# HSM_HSM_AES_CE006000h register map
Vendor: Texas Instruments
Peripheral module from a debugger description file (folder AM261x).
Registers are 32-bit, read-write, reset 0x0 unless marked. A register's access mark holds for its fields unless they carry their own. Offsets are as the file gives them; lines under a group give offsets from that group; [hi:lo] are bit positions; {n}, {i} and the like mark numbered series; 'fields as' and 'values as' point back to an identical list; <NAME> marks a mode.

## HSM_AES
0x00 HSM_AES_S_KEY2_6 — XTS second key / CBC-MAC third key (Read-returns0s).
  [31:0] KEY — key data
0x04 HSM_AES_S_KEY2_7 — XTS second key (MSW for 256-bit key) / CBC-MAC third key (MSW) (Read-returns0s).
  [31:0] KEY — key data
0x08 HSM_AES_S_KEY2_4 — XTS / CCM second key / CBC-MAC third key (LSW) (Read-returns0s).
  [31:0] KEY — key data
0x0C HSM_AES_S_KEY2_5 — XTS second key (MSW for 192-bit key) / CBC-MAC third key (Read-returns0s).
  [31:0] KEY — key data
0x10 HSM_AES_S_KEY2_2 — XTS / CCM / CBC-MAC second key / Hash Key input (Read-returns0s).
  [31:0] KEY — key data
0x14 HSM_AES_S_KEY2_3 — XTS second key (MSW for 128-bit key) + CCM/CBC-MAC second key (MSW) / Hash Key input (MSW) (Read-returns0s).
  [31:0] KEY — key data
0x18 HSM_AES_S_KEY2_0 — XTS / CCM / CBC-MAC second key (LSW) / Hash Key input (LSW) (Read-returns0s).
  [31:0] KEY — key data
0x1C HSM_AES_S_KEY2_1 — XTS / CCM / CBC-MAC second key / Hash Key input (Read-returns0s).
  [31:0] KEY — key data
0x20 HSM_AES_S_KEY1_6 — Key (LSW for 256-bit key) (Read-returns0s).
  [31:0] KEY — key data
0x24 HSM_AES_S_KEY1_7 — Key (MSW for 256-bit key) (Read-returns0s).
  [31:0] KEY — key data
0x28 HSM_AES_S_KEY1_4 — Key (LSW for 192-bit key) (Read-returns0s).
  [31:0] KEY — key data
0x2C HSM_AES_S_KEY1_5 — Key (MSW for 192-bit key) (Read-returns0s).
  [31:0] KEY — key data
0x30 HSM_AES_S_KEY1_2 — Key (Read-returns0s).
  [31:0] KEY — key data
0x34 HSM_AES_S_KEY1_3 — Key (MSW for 128-bit key) (Read-returns0s).
  [31:0] KEY — key data
0x38 HSM_AES_S_KEY1_0 — Key (LSW for 128-bit key) (Read-returns0s).
  [31:0] KEY — key data
0x3C HSM_AES_S_KEY1_1 — Key (Read-returns0s).
  [31:0] KEY — key data
0x40 HSM_AES_S_IV_IN_0 — Initialization Vector input (LSW).
  [31:0] DATA — IV data
0x44 HSM_AES_S_IV_IN_1 — Initialization vector input.
  [31:0] DATA — IV data
0x48 HSM_AES_S_IV_IN_2 — Initialization vector input .
  [31:0] DATA — IV data
0x4C HSM_AES_S_IV_IN_3 — Initialization Vector input (MSW)
  [31:0] DATA — IV data
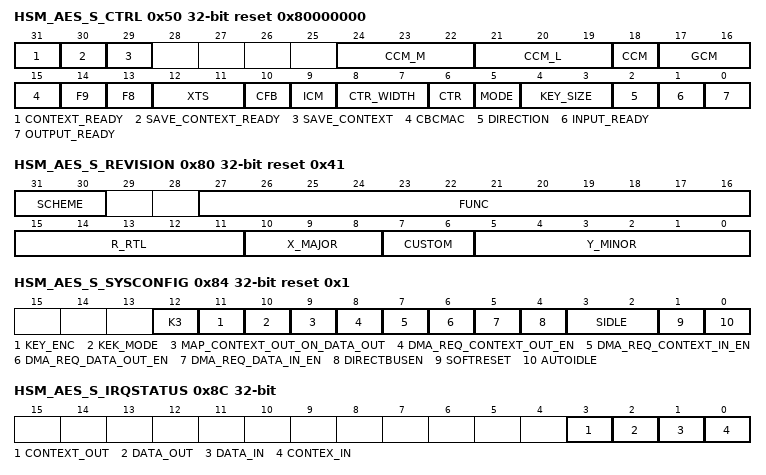
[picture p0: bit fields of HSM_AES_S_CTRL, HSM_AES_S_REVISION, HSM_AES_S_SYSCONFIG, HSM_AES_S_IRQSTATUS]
0x50 HSM_AES_S_CTRL access per field reset 0x80000000 — Register determines the mode of operation of the AES Engine.
  [31] CONTEXT_READY ro — If'1' this read-only status bit indicates that the context data registers can be overwritten and the host is permitted to write the next context.
  [30] SAVE_CONTEXT_READY ro — If'1' this read-only status bit indicates that an AES authentication TAG and/or IV block[s] is/are available for the host to retrieve. This bit is only asserted if the'save_context' bit is set to'1'. The bit is mutual exclusive with the'context_ready' bit.
  [29] SAVE_CONTEXT rw — This bit is used to indicate that an authentication TAG or result IV needs to be stored as a result context. If this bit is set context output DMA and/or interrupt will be asserted if the operation is finished and related signals are enabled.
  [24:22] CCM_M rw — Defines 'M' that indicated the length of the authentication field for CCM operations; the authentication field length equals two times [the value of CCM-M plus one]. Note that the AES Engine always returns a 128-bit authentication field of which the M least significant bytes are valid. All values are supported.
  [21:19] CCM_L rw — Defines 'L' that indicated the width of the length field for CCM operations; the length field in bytes equals the value of CMM-L plus one. Supported values for L are [programmed value]: 2 [1] 4 [3] and 8 [7].
  [18] CCM rw — AES-CCM is selected this is a combined mode using AES for both authentication and encryption. No additional mode selection is required. 0 Other mode selected 1 ccm mode selected
  [17:16] GCM rw — AES-GCM mode is selected.this is a combined mode using the Galois field multiplier GF[2^128] for authentication and AES-CTR mode for encryption the bits specify the GCM mode. 0x0 No operation 0x1 GHASH with H loaded and Y0-encrypted forced to zero 0x2 GHASH with H loaded and Y0-encrypted calculated internally 0x3 Autonomous GHASH [both H and Y0-encrypted calculated internally]
  [15] CBCMAC rw — AES-CBC MAC is selected the Direction bit must be set to'1' for this mode. 0 Other mode selected 1 cbcmac mode selected
  [14] F9 rw — AES f9 mode is selected the AES key size must be set to 128-bit for this mode. 0 Other mode selected 1 f9 selected
  [13] F8 rw — AES f8 mode is selected the AES key size must be set to 128-bit for this mode. 0 Other mode selected 1 f8 selected
  [12:11] XTS rw — AES-XTS operation is selected; the bits specify the XTS mode.01 = Previous/intermediate tweak value and'j' loaded [value is loaded via IV j is loaded via the AAD length register] 0x0 No operation 0x1 Previous/intermediate tweak value and'j' loaded [value is loaded via IV j is loaded via the AAD length register] 0x2 Key2 i and j loaded [i is loaded via IV j is loaded via the AAD length register] 0x3 Key2 and i loaded j=0 [i is loaded via IV]
  [10] CFB rw — full block AES cipher feedback mode [CFB128] is selected. 0 other mode selected 1 cfb selected
  [9] ICM rw — AES integer counter mode [ICM] is selected this is a counter mode with a 16-bit wide counter. 0 Other mode selected. 1 ICM mode selected
  [8:7] CTR_WIDTH rw — Specifies the counter width for AES-CTR mode 0x0 Counter is 32 bits 0x1 Counter is 64 bits 0x2 Counter is 128 bits 0x3 Counter is 192 bits
  [6] CTR rw — Tthis bit must also be set for GCM and CCM when encryption/decryption is required. 0 Other mode selected 1 Counter mode
  [5] MODE rw — Ecb/cbc mode 0 ecb mode 1 cbc mode
  [4:3] KEY_SIZE rw — key size 0x0 reserved 0x1 Key is 128 bits. 0x2 Key is 192 bits 0x3 Key is 256
  [2] DIRECTION rw — If set to'1' an encrypt operation is performed. If set to'0' a decrypt operation is performed. Read0 decryption is selected Read1 Encryption is selected
  [1] INPUT_READY ro — If'1' this read-only status bit indicates that the 16-byte input buffer is empty and the host is permitted to write the next block of data.
  [0] OUTPUT_READY ro — If'1' this read-only status bit indicates that an AES output block is available for the host to retrieve.
0x54 HSM_AES_S_C_LENGTH_0 — Crypto data length registers (LSW and MSW) store the cryptographic data length in bytes for all modes. Once processing with this context is started this length decrements to zero. Data lengths up to (2^61- 1) bytes are allowed. For GCM any value up to 2^36 - 32 bytes can be used. This is because a 32-bit counter mode is used; the maximum number of 128-bit blocks is 2^32- 2 resulting in a maximum number of bytes of 2^36 - 32. A write to this register triggers the engine to start using this context. This is valid for all modes except GCM and CCM. Note that for the combined modes this length does not include the authentication only data; the authentication length is specified in the AES_AUTH_LENGTH register below. All modes must have a length > 0. For the combined modes it is allowed to have one of the lengths equal to zero. For the basic encryption modes (ECB/CBC/CTR/ICM/CFB128) it is allowed to program zero to the length field; in that case the length is assumed infinite. All data must be byte (8-bit) aligned; bit aligned data streams are not supported by the AES Engine. For a Host read operation these registers return all-zeroes. (Read-returns0s).
  [31:0] RESERVED — Data length [LSW]
0x58 HSM_AES_S_C_LENGTH_1 — Crypto data length registers (LSW and MSW) store the cryptographic data length in bytes for all modes. Once processing with this context is started this length decrements to zero. Data lengths up to (2^61- 1) bytes are allowed. For GCM any value up to 2^36 - 32 bytes can be used. This is because a 32-bit counter mode is used; the maximum number of 128-bit blocks is 2^32- 2 resulting in a maximum number of bytes of 2^36 - 32. A write to this register triggers the engine to start using this context. This is valid for all modes except GCM and CCM. Note that for the combined modes this length does not include the authentication only data; the authentication length is specified in the AES_AUTH_LENGTH register below. All modes must have a length > 0. For the combined modes it is allowed to have one of the lengths equal to zero. For the basic encryption modes (ECB/CBC/CTR/ICM/CFB128) it is allowed to program zero to the length field; in that case the length is assumed infinite. All data must be byte (8-bit) aligned; bit aligned data streams are not supported by the AES Engine. For a Host read operation these registers return all-zeroes. (Read-returns0s).
  [28:0] LENGTH — Data length [MSW] length registers [LSW and MSW] store the cryptographic data length in bytes for all modes. Once processing with this context is started this length decrements to zero. Data lengths up to [2^61 - 1] bytes are allowed. For GCM any value up to 2^36 - 32 bytes can be used. This is because a 32-bit counter mode is used; the maximum number of 128-bit blocks is 2^32 - 2 resulting in a maximum number of bytes of 2^36 - 32. A write to this register triggers the engine to start using this context. This is valid for all modes except GCM and CCM. Note that for the combined modes this length does not include the authentication only data; the authentication length is specified in the AES_AUTH_LENGTH register below. All modes must have a length > 0. For the combined modes it is allowed to have one of the lengths equal to zero. For the basic encryption modes [ECB/CBC/CTR/ICM/CFB128] it is allowed to program zero to the length field; in that case the length is assumed infinite. All data must be byte [8-bit] aligned; bit aligned data streams are not supported by the AES Engine. For a Host read operation these registers return all-zeroes.
0x5C HSM_AES_S_AUTH_LENGTH — AAD data length. The authentication length register store the authentication data length in bytes for combined modes only (GCM or CCM) Supported AAD-lengths for CCM are from 0 to (2^16 - 2^8) bytes. For GCM any value up to (2^32 - 1) bytes can be used. Once processing with this context is started this length decrements to zero. A write to this register triggers the engine to start using this context for GCM and CCM. For XTS this register is optionally used to load 'j'. Loading of 'j' is only required if 'j' != 0. 'j' is a 28-bit value and must be written to bits [31-4] of this register. 'j' represents the sequential number of the 128-bit block inside the data unit. For the first block in a unit this value is zero. It is not required to provide a 'j' for each new data block within a unit. Note that it is possible to start with a 'j' unequal to zero; refer to Table 4 for more details. For a Host read operation these registers return all-zeroes. (Read-returns0s).
  [31:0] AUTH — data
0x60 HSM_AES_S_DATA_IN_0 — Data register to read and write plaintext/ciphertext (MSW).
  [31:0] DATA — Data to encrypt/decrypt
0x64 HSM_AES_S_DATA_IN_1 — Data register to read and write plaintext/ciphertext.
  [31:0] DATA — Data to encrypt/decrypt
0x68 HSM_AES_S_DATA_IN_2 — Data register to read and write plaintext/ciphertext.
  [31:0] DATA — Data to encrypt/decrypt
0x6C HSM_AES_S_DATA_IN_3 — Data register to read and write plaintext/ciphertext (LSW).
  [31:0] DATA — Data to encrypt/decrypt
{0x70+4i} HSM_AES_S_TAG_OUT_{i} (i=0..2) — Hash result (MSW).
  [31:0] HASH — Hash result [MSW]
0x7C HSM_AES_S_TAG_OUT_3 — Hash result (MSW).
  [31:0] HASH — Hash result [LSW]
0x80 HSM_AES_S_REVISION ro reset 0x41 — Register AES_REVISION.
  [31:30] SCHEME — Used to distinguish between old scheme and current. Read0x0 Legacy ASP or WTBU scheme Read0x1 Highlander 0.8 scheme
  [27:16] FUNC — Function indicates a software compatible module family. If there is no level of software compatibility a new Func number [and hence REVISION] should be assigned.
  [15:11] R_RTL — RTL Version [R] maintained by IP design owner. RTL follows a numbering such as X.Y.R.Z which are explained in this table. R changes ONLY when: [1] PDS uploads occur which may have been due to spec changes [2] Bug fixes occur [3] Resets to '0' when X or Y changes. Design team has an internal 'Z' [customer invisible] number which increments on every drop that happens due to DV and RTL updates. Z resets to 0 when R increments.
  [10:8] X_MAJOR — Major Revision [X] maintained by IP specification owner. X changes ONLY when: [1] There is a major feature addition. An example would be adding Master Mode to Utopia Level2. The Func field [or Class/Type in old PID format] will remain the same. X does NOT change due to: [1] Bug fixes [2] Change in feature parameters.
  [7:6] CUSTOM — Indicates a special version for a particular device. Consequence of use may avoid use of standard Chip Support Library [CSL] / Drivers. Read0x0 Non custom [standard] revision
  [5:0] Y_MINOR — Minor Revision [Y] maintained by IP specification owner. Y changes ONLY when: [1] Features are scaled [up or down]. Flexibility exists in that this feature scalability may either be represented in the Y change or a specific register in the IP that indicates which features are exactly available. [2] When feature creeps from Is-Not list to Is list. But this may not be the case once it sees silicon; in which case X will change. Y does NOT change due to: [1] Bug fixes [2] Typos or clarifications [3] major functional/feature change/addition/deletion. Instead these changes may be reflected via R S X as applicable. Spec owner maintains a customer-invisible number 'S' which changes due to: [1] Typos/clarifications [2] Bug documentation. Note that this bug is not due to a spec change but due to implementation. Nevertheless the spec tracks the IP bugs. An RTL release [say for silicon PG1.1] that occurs due to bug fix should document the corresponding spec number [X.Y.S] in its release notes.
0x84 HSM_AES_S_SYSCONFIG reset 0x1 — Register AES_SYSCONFIG.This register configures the DMA signals and controls the IDLE and reset logic.
  [12] K3 — If this bit is set to zero, a regular cryptographic operation is performed.This bit may be set to one only if bit directbusen of this register and bit key_enc of this register are cleared to zero. If this bit is one, the K3 key is used as key for the selected cryptographic operation.If this mode is selected, the key size should be 128-bit.
  [11] KEY_ENC — If this bit is set to zero, a regular cryptographic operation is performed.This bit may be set to one only if bit directbusen of this register is cleared to zero. If this bit is'1', the KEK [see description of bit kek_mode] key is XOR-ed with a predefined constant value before it is used as key for the selected cryptographic operation.
  [10] KEK_MODE — If this bit is zero, the direct key is used directly for the selected cryptographic operation, if it is selected by enabling directbusen of this register. If the direct key is not selected, a regular operation is performed.This bit may be set to one only if bit directbusen is set to'1'. If this bit is to one and the direct key bit is selected, the direct key is XOR-ed with a predefined constant value [constant1 ] before it is used as key for the cryptographic operation. If both bits are set to'1', the direction of the cryptographic operation is forced to'encryption' [independent of the programmed direction in the AES_S_CTRL register]. The result of the operation with this XOR-ed key is automatically stored in a separate internal key register [KEK]. No output data is provided in this case; Reading from the data output register returns zeroes.If this mode is selected, the cryptographic mode should be set to ECB and the key size should be 128-bit.Please refer to Appendix A.5 for details on the key selection mechanism.Note that for correct behavior of the core, this bit should only be changed if the core is ready for a new context on the secure HIB.
  [9] MAP_CONTEXT_OUT_ON_DATA_OUT — If set to '1' the two context out requests [dma_req_context_out_en Bit [8] above and context_out interrupt enable Bit [3] of AES_IRQENABLE register] are mapped on the corresponding data output request bit. In this case the original'context out' bit values are ignored.
  [8] DMA_REQ_CONTEXT_OUT_EN — If set to'1' the DMA context output request is enabled [for context data out e.g. TAG for authentication modes]. 0 Dma disabled 1 Dma enabled
  [7] DMA_REQ_CONTEXT_IN_EN — If set to'1' the DMA context request is enabled. 0 Dma disabled 1 Dma enabled
  [6] DMA_REQ_DATA_OUT_EN — If set to'1' the DMA output request is enabled. 0 Dma disabled 1 Dma enabled
  [5] DMA_REQ_DATA_IN_EN — If set to'1' the DMA input request is enabled. 0 Dma disabled 1 Dma enabled
  [4] DIRECTBUSEN — keys from register or directbus input0: Use the key registers 1: Use the directbus
  [3:2] SIDLE — Sidle mode0x0: Force Idle mode. 0x1: No idle 0x2: Smart Idle mode 0x3: reserved
  [1] SOFTRESET — Softreset0: No operation. 1: When '1', starts softreset sequnce.
  [0] AUTOIDLE — Autoidle 0: When '0', internal clocks are running. 1: When '1', internal clocks are cut.
0x88 HSM_AES_S_SYSSTATUS reset 0x1 — System status.
  [0] RESETDONE
0x8C HSM_AES_S_IRQSTATUS — This register indicates the interrupt status. If one of the interrupt bits is set the interrupt output will be asserted.
  [3] CONTEXT_OUT — This bit indicates authentication tag [and IV] interrupt[s] is/are active and triggers the interrupt output.
  [2] DATA_OUT — This bit indicates data output interrupt is active and triggers the interrupt output.
  [1] DATA_IN — This bit indicates data input interrupt is active and triggers the interrupt output.
  [0] CONTEX_IN — This bit indicates context interrupt is active and triggers the interrupt output.
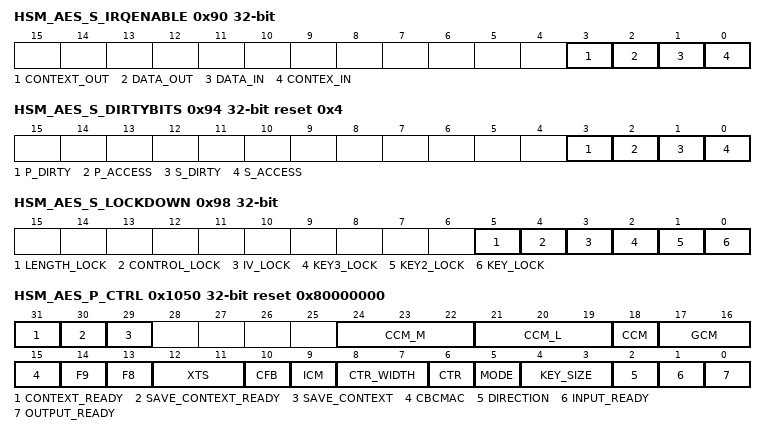
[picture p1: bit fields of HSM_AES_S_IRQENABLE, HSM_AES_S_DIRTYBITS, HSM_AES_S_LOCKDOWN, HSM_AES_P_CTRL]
0x90 HSM_AES_S_IRQENABLE — This register contains an enable bit for each unique interrupt generated by the module. It matches the layout of AES_IRQSTATUS register. An interrupt is enabled when the bit in this register is set to '1'. An interrupt that is enabled is propagated to the SINTREQUEST_x output. All interrupts need to be enabled explicitly by writing this register.
  fields as HSM_AES_S_IRQSTATUS
0x94 HSM_AES_S_DIRTYBITS ro reset 0x4 — Read/Write Access control.
  [3] P_DIRTY — This bit is set to 1 by the module if any of the AES P_* registers is written.
  [2] P_ACCESS — This bit is set to 1 by the module if any of the AES P_* registers is read.
  [1] S_DIRTY — This bit is set to 1 by the module if any of the AES S_* registers is written except AES_S_DIRTYBITS and AES_S_LOCKDOWN.
  [0] S_ACCESS — This bit is set to 1 by the module if any of the AES S_* registers is read except AES_S_DIRTYBITS and AES_S_LOCKDOWN.
0x98 HSM_AES_S_LOCKDOWN — Use this register to prevent further access /Lock Register.
  [5] LENGTH_LOCK — If set to'1' the DES_P length registers can not be written [this lock involves word address from 0x1054 to 0x105c].
  [4] CONTROL_LOCK — If set to'1' the AES_P control register can not be written [this lock involves word address 0x1050].
  [3] IV_LOCK — If set to'1' the AES_P IV registers cannot be written [this lock involves word addresses 0x1040 up to 0x104C].
  [2] KEY3_LOCK — If set to'1' the AES_P key3 registers cannot be written [this lock involves word addresses 0x1030 up to 0x103C].
  [1] KEY2_LOCK — If set to'1' the AES_P key2 registers cannot be written [this lock involves word addresses 0x1020 up to 0x102C].
  [0] KEY_LOCK — If set to'1' the AES_P key registers cannot be written [this lock involves word addresses 0x1000 up to 0x101C].
0x1000 HSM_AES_P_KEY2_6 — XTS second key / CBC-MAC third key (Read-returns0s).
  [31:0] KEY — key data
0x1004 HSM_AES_P_KEY2_7 — XTS second key (MSW for 256-bit key) / CBC-MAC third key (MSW) (Read-returns0s).
  [31:0] KEY — key data
0x1008 HSM_AES_P_KEY2_4 — XTS / CCM second key / CBC-MAC third key (LSW) (Read-returns0s).
  [31:0] KEY — key data
0x100C HSM_AES_P_KEY2_5 — XTS second key (MSW for 192-bit key) / CBC-MAC third key (Read-returns0s).
  [31:0] KEY — key data
0x1010 HSM_AES_P_KEY2_2 — XTS / CCM / CBC-MAC second key / Hash Key input (Read-returns0s).
  [31:0] KEY — key data
0x1014 HSM_AES_P_KEY2_3 — XTS second key (MSW for 128-bit key) + CCM/CBC-MAC second key (MSW) / Hash Key input (MSW) (Read-returns0s).
  [31:0] KEY — key data
0x1018 HSM_AES_P_KEY2_0 — XTS / CCM / CBC-MAC second key (LSW) / Hash Key input (LSW) (Read-returns0s).
  [31:0] KEY — key data
0x101C HSM_AES_P_KEY2_1 — XTS / CCM / CBC-MAC second key / Hash Key input (Read-returns0s).
  [31:0] KEY — key data
0x1020 HSM_AES_P_KEY1_6 — Key (LSW for 256-bit key) (Read-returns0s).
  [31:0] KEY — key data
0x1024 HSM_AES_P_KEY1_7 — Key (MSW for 256-bit key) (Read-returns0s).
  [31:0] KEY — key data
0x1028 HSM_AES_P_KEY1_4 — Key (LSW for 192-bit key) (Read-returns0s).
  [31:0] KEY — key data
0x102C HSM_AES_P_KEY1_5 — Key (MSW for 192-bit key) (Read-returns0s).
  [31:0] KEY — key data
0x1030 HSM_AES_P_KEY1_2 — Key (Read-returns0s).
  [31:0] KEY — key data
0x1034 HSM_AES_P_KEY1_3 — Key (MSW for 128-bit key) (Read-returns0s).
  [31:0] KEY — key data
0x1038 HSM_AES_P_KEY1_0 — Key (LSW for 128-bit key) (Read-returns0s).
  [31:0] KEY — key data
0x103C HSM_AES_P_KEY1_1 — Key (Read-returns0s).
  [31:0] KEY — key data
0x1040 HSM_AES_P_IV_IN_0 — Initialization Vector input (LSW).
  [31:0] DATA — IV data
0x1044 HSM_AES_P_IV_IN_1 — Initialization vector input.
  [31:0] DATA — IV data
0x1048 HSM_AES_P_IV_IN_2 — Initialization vector input.
  [31:0] DATA — IV data
0x104C HSM_AES_P_IV_IN_3 — Initialization Vector input (MSW).
  [31:0] DATA — IV data
0x1050 HSM_AES_P_CTRL access per field reset 0x80000000 — Register determines the mode of operation of the AES Engine.
  fields as HSM_AES_S_CTRL
0x1054 HSM_AES_P_C_LENGTH_0 — Crypto data length registers (LSW and MSW) store the cryptographic data length in bytes for all modes. Once processing with this context is started this length decrements to zero. Data lengths up to (2^61-1) bytes are allowed. For GCM any value up to 2^36 - 32 bytes can be used. This is because a 32-bit counter mode is used; the maximum number of 128-bit blocks is 2^32-2 resulting in a maximum number of bytes of 2^36 - 32. A write to this register triggers the engine to start using this context. This is valid for all modes except GCM and CCM. Note that for the combined modes this length does not include the authentication only data; the authentication length is specified in the AES_AUTH_LENGTH register below. All modes must have a length > 0. For the combined modes it is allowed to have one of the lengths equal to zero. For the basic encryption modes (ECB/CBC/CTR/ICM/CFB128) it is allowed to program zero to the length field; in that case the length is assumed infinite. All data must be byte (8-bit) aligned; bit aligned data streams are not supported by the AES Engine. For a Host read operation these registers return all-zeroes. (Read-returns0s).
  [31:0] RESERVED — Data length [LSW]
0x1058 HSM_AES_P_C_LENGTH_1 — Crypto data length registers (LSW and MSW) store the cryptographic data length in bytes for all modes. Once processing with this context is started this length decrements to zero. Data lengths up to (2^61-1) bytes are allowed. For GCM any value up to 2^36 - 32 bytes can be used. This is because a 32-bit counter mode is used; the maximum number of 128-bit blocks is 2^32-2 resulting in a maximum number of bytes of 2^36 - 32. A write to this register triggers the engine to start using this context. This is valid for all modes except GCM and CCM. Note that for the combined modes this length does not include the authentication only data; the authentication length is specified in the AES_AUTH_LENGTH register below. All modes must have a length > 0. For the combined modes it is allowed to have one of the lengths equal to zero. For the basic encryption modes (ECB/CBC/CTR/ICM/CFB128) it is allowed to program zero to the length field; in that case the length is assumed infinite. All data must be byte (8-bit) aligned; bit aligned data streams are not supported by the AES Engine. For a Host read operation these registers return all-zeroes. (Read-returns0s).
  fields as HSM_AES_S_C_LENGTH_1
0x105C HSM_AES_P_AUTH_LENGTH — AAD data length. The authentication length register store the authentication data length in bytes for combined modes only (GCM or CCM) Supported AAD-lengths for CCM are from 0 to (2^16 - 2^8) bytes. For GCM any value up to (2^32 - 1) bytes can be used. Once processing with this context is started this length decrements to zero. A write to this register triggers the engine to start using this context for GCM and CCM. For XTS this register is optionally used to load 'j'. Loading of 'j' is only required if 'j' != 0. 'j' is a 28-bit value and must be written to bits [31-4] of this register. 'j' represents the sequential number of the 128-bit block inside the data unit. For the first block in a unit this value is zero. It is not required to provide a 'j' for each new data block within a unit. Note that it is possible to start with a 'j' unequal to zero; refer to Table 4 for more details. For a Host read operation these registers return all-zeroes. (Read-returns0s).
  [31:0] AUTH — data
0x1060 HSM_AES_P_DATA_IN_0 — Data register to read and write plaintext/ciphertext (MSW).
  [31:0] DATA — Data to encrypt/decrypt
0x1064 HSM_AES_P_DATA_IN_1 — Data register to read and write plaintext/ciphertext.
  [31:0] DATA — Data to encrypt/decrypt
0x1068 HSM_AES_P_DATA_IN_2 — Data register to read and write plaintext/ciphertext.
  [31:0] DATA — Data to encrypt/decrypt
0x106C HSM_AES_P_DATA_IN_3 — Data register to read and write plaintext/ciphertext (LSW).
  [31:0] DATA — Data to encrypt/decrypt
{0x1070+4i} HSM_AES_P_TAG_OUT_{i} (i=0..2) — Hash result (MSW).
  [31:0] HASH — Hash result [MSW]
0x107C HSM_AES_P_TAG_OUT_3 — Hash result (MSW).
  [31:0] HASH — Hash result [LSW]
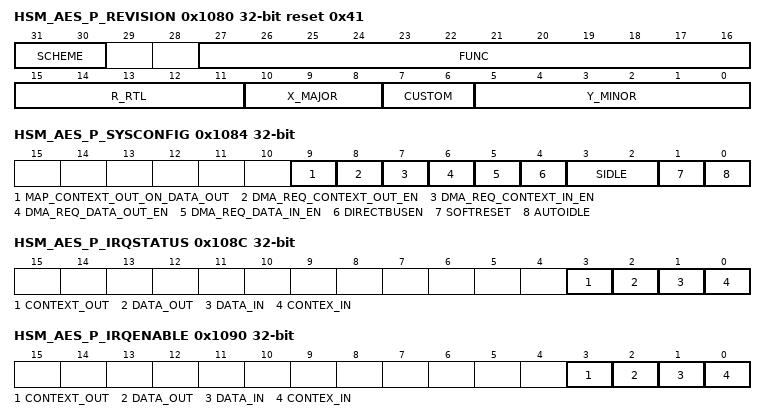
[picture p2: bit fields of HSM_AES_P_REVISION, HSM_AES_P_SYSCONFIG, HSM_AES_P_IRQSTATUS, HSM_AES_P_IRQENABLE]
0x1080 HSM_AES_P_REVISION ro reset 0x41 — Register AES_REVISION.
  fields as HSM_AES_S_REVISION
0x1084 HSM_AES_P_SYSCONFIG — Register AES_SYSCONFIG.This register configures the DMA signals and controls the IDLE and reset logic.
  [9] MAP_CONTEXT_OUT_ON_DATA_OUT — If set to '1' the two context out requests [dma_req_context_out_en Bit [8] above and context_out interrupt enable Bit [3] of AES_IRQENABLE register] are mapped on the corresponding data output request bit. In this case the original'context out' bit values are ignored.
  [8] DMA_REQ_CONTEXT_OUT_EN — If set to'1' the DMA context output request is enabled [for context data out e.g. TAG for authentication modes]. 0 Dma disabled 1 Dma enabled
  [7] DMA_REQ_CONTEXT_IN_EN — If set to'1' the DMA context request is enabled. 0 Dma disabled 1 Dma enabled
  [6] DMA_REQ_DATA_OUT_EN — If set to'1' the DMA output request is enabled. 0 Dma disabled 1 Dma enabled
  [5] DMA_REQ_DATA_IN_EN — If set to'1' the DMA input request is enabled. 0 Dma disabled 1 Dma enabled
  [4] DIRECTBUSEN — keys from register or directbus input0: Use the key registers 1: Use the directbus
  [3:2] SIDLE — Sidle mode0x0: Force Idle mode. 0x1: No idle 0x2: Smart Idle mode 0x3: reserved
  [1] SOFTRESET — Softreset0: No operation. 1: When '1', starts softreset sequnce.
  [0] AUTOIDLE — Autoidle 0: When '0', internal clocks are running. 1: When '1', internal clocks are cut.
0x1088 HSM_AES_P_SYSSTATUS — System status.
  [0] RESETDONE — Indicates reset done
0x108C HSM_AES_P_IRQSTATUS — This register indicates the interrupt status. If one of the interrupt bits is set the interrupt output will be asserted.
  fields as HSM_AES_S_IRQSTATUS
0x1090 HSM_AES_P_IRQENABLE — This register contains an enable bit for each unique interrupt generated by the module. It matches the layout of AES_IRQSTATUS register. An interrupt is enabled when the bit in this register is set to '1'. An interrupt that is enabled is propagated to the SINTREQUEST_x output. All interrupts need to be enabled explicitly by writing this register.
  fields as HSM_AES_S_IRQSTATUS
